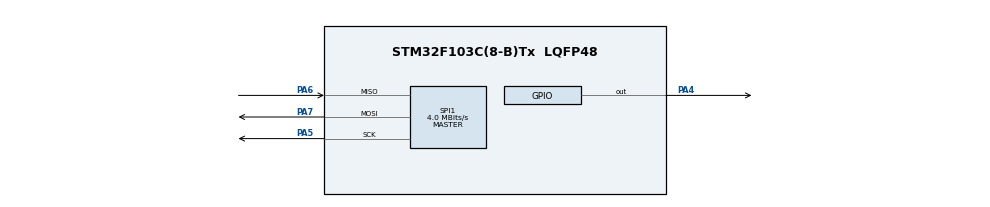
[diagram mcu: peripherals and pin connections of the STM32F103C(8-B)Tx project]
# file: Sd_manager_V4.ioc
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FATFS._MAX_SS=4096
FATFS._USE_LFN=1
Mcu.Family=STM32F1
Mcu.Name=STM32F103C(8-B)Tx
Mcu.Package=LQFP48
NVIC.PriorityGroup=NVIC_PRIORITYGROUP_4
PA13.Mode=Serial_Wire
PA13.Signal=SYS_JTMS-SWDIO
PA14.Mode=Serial_Wire
PA14.Signal=SYS_JTCK-SWCLK
PA4.Signal=GPIO_Output
PA5.Mode=Full_Duplex_Master
PA5.Signal=SPI1_SCK
PA6.Mode=Full_Duplex_Master
PA6.Signal=SPI1_MISO
PA7.Mode=Full_Duplex_Master
PA7.Signal=SPI1_MOSI
ProjectManager.HeapSize=0x200
ProjectManager.StackSize=0x400
ProjectManager.TargetToolchain=STM32CubeIDE
RCC.APB1Freq_Value=8000000
RCC.APB2Freq_Value=8000000
SPI1.CalculateBaudRate=4.0 MBits/s
SPI1.Direction=SPI_DIRECTION_2LINES
SPI1.Mode=SPI_MODE_MASTER
SPI1.VirtualType=VM_MASTER
VP_FATFS_VS_Generic.Mode=User_defined
board=custom

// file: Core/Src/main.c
/* USER CODE BEGIN Header */
/**
  ******************************************************************************
  * @file           : main.c
  * @brief          : Main program body
  ******************************************************************************
  * @attention
  *
  * Copyright (c) 2024 STMicroelectronics.
  * All rights reserved.
  *
  * This software is licensed under terms that can be found in the LICENSE file
  * in the root directory of this software component.
  * If no LICENSE file comes with this software, it is provided AS-IS.
  *
  ******************************************************************************
  */
/* USER CODE END Header */
#include "main.h"
#include "fatfs.h"

#include <stdio.h>

#include "sd_nextion_lib.h"

/* USER CODE BEGIN PTD */
int case_index = 0;
/* USER CODE END PTD */

/* USER CODE BEGIN PD */
FATFS fs;

/* USER CODE END PD */

SPI_HandleTypeDef hspi1;

void SystemClock_Config(void);
static void MX_GPIO_Init(void);
static void MX_SPI1_Init(void);

int main(void)
{

  /* MCU Configuration--------------------------------------------------------*/

  /* Reset of all peripherals, Initializes the Flash interface and the Systick. */
  HAL_Init();

  /* Configure the system clock */
  SystemClock_Config();

  /* Initialize all configured peripherals */
  MX_GPIO_Init();
  MX_SPI1_Init();
  MX_FATFS_Init();
  /* USER CODE BEGIN 2 */

  /* WRITE TEST CSV FILE */
  //HAL_Delay(500);
  //f_mount(&fs, "", 0);
  //f_open(&fil, "filePrueba.csv", FA_OPEN_ALWAYS | FA_WRITE | FA_READ);
  //f_lseek(&fil, fil.fsize);
  //f_puts("Dato1,Dato2,Dato3\n", &fil);
  //f_close(&fil);

  // Montar el sistema de archivos
  if (f_mount(&fs, "", 0) != FR_OK) {
      // Manejar el error de montaje del sistema de archivos
      Error_Handler();
  }

  save_sd(0,"MCU initialized", "timestamp");

  if (verificarSd("data.csv") == 1) {
	  printf("OK: Se pudo acceder a data.csv\n");
  } else {
	  // Manejar el error: archivo no disponible
	  printf("KO: No se pudo acceder a data.csv\n");
  }

  /* USER CODE END 2 */

  /* Infinite loop */
  /* USER CODE BEGIN WHILE */
  while (1)
  {

	 /* Toggle the LED */
	 HAL_GPIO_TogglePin(GPIOC, GPIO_PIN_13);
	 HAL_Delay(200);

	 switch (case_index) {
	 	  case 0:
	 		  //ID_Engine_temp
	 		  save_sd(1, "Engine_temp_Value", "timestamp");
	 		  break;
	 	  case 1:
	 		  //Battery_volt
	 		  save_sd(2, "Valor_Battery_volt_Value", "timestamp");
	 		  break;
	 	  case 2:
	 		  //Speed
	 		  save_sd(3, "Valor_Speed_Value", "timestamp");
	 		  break;
	 	  case 3:
	 		  //Gear
	 		  save_sd(4, "Valor_Gear_Value", "timestamp");
	 		  break;
	 	  case 4:
	 		  //RPMs
	 		  save_sd(5, "Valor_RPM_Value", "timestamp");
	 		  break;
	 	  case 5:
	 		  //Brake_pedal
	 		  save_sd(6, "Valor_Brake_pedal_Value", "timestamp" );
	 		  break;
	 	  case 6:
	 		  //Accel_pedal
	 		  save_sd(7,"Valor_Accel_pedal_Value", "timestamp");
	 		  break;
	 	  default:
	 		  // Manejar el caso por defecto si case_index está fuera de rango
	 		  Error_Handler();
	 		  break;
	   }
	case_index++;
	if (case_index == 7) {
	    case_index = 0;
	}

  }
  /* USER CODE END 3 */
}

void SystemClock_Config(void)
{
  RCC_OscInitTypeDef RCC_OscInitStruct = {0};
  RCC_ClkInitTypeDef RCC_ClkInitStruct = {0};

  /** Initializes the RCC Oscillators according to the specified parameters
  * in the RCC_OscInitTypeDef structure.
  */
  RCC_OscInitStruct.OscillatorType = RCC_OSCILLATORTYPE_HSI;
  RCC_OscInitStruct.HSIState = RCC_HSI_ON;
  RCC_OscInitStruct.HSICalibrationValue = RCC_HSICALIBRATION_DEFAULT;
  RCC_OscInitStruct.PLL.PLLState = RCC_PLL_NONE;
  if (HAL_RCC_OscConfig(&RCC_OscInitStruct) != HAL_OK)
  {
    Error_Handler();
  }

  /** Initializes the CPU, AHB and APB buses clocks
  */
  RCC_ClkInitStruct.ClockType = RCC_CLOCKTYPE_HCLK|RCC_CLOCKTYPE_SYSCLK
                              |RCC_CLOCKTYPE_PCLK1|RCC_CLOCKTYPE_PCLK2;
  RCC_ClkInitStruct.SYSCLKSource = RCC_SYSCLKSOURCE_HSI;
  RCC_ClkInitStruct.AHBCLKDivider = RCC_SYSCLK_DIV1;
  RCC_ClkInitStruct.APB1CLKDivider = RCC_HCLK_DIV1;
  RCC_ClkInitStruct.APB2CLKDivider = RCC_HCLK_DIV1;

  if (HAL_RCC_ClockConfig(&RCC_ClkInitStruct, FLASH_LATENCY_0) != HAL_OK)
  {
    Error_Handler();
  }
}

static void MX_SPI1_Init(void)
{

  /* SPI1 parameter configuration*/
  hspi1.Instance = SPI1;
  hspi1.Init.Mode = SPI_MODE_MASTER;
  hspi1.Init.Direction = SPI_DIRECTION_2LINES;
  hspi1.Init.DataSize = SPI_DATASIZE_8BIT;
  hspi1.Init.CLKPolarity = SPI_POLARITY_LOW;
  hspi1.Init.CLKPhase = SPI_PHASE_1EDGE;
  hspi1.Init.NSS = SPI_NSS_SOFT;
  hspi1.Init.BaudRatePrescaler = SPI_BAUDRATEPRESCALER_2;
  hspi1.Init.FirstBit = SPI_FIRSTBIT_MSB;
  hspi1.Init.TIMode = SPI_TIMODE_DISABLE;
  hspi1.Init.CRCCalculation = SPI_CRCCALCULATION_DISABLE;
  hspi1.Init.CRCPolynomial = 10;
  if (HAL_SPI_Init(&hspi1) != HAL_OK)
  {
    Error_Handler();
  }

}

static void MX_GPIO_Init(void)
{
  GPIO_InitTypeDef GPIO_InitStruct = {0};

  /* GPIO Ports Clock Enable */
  __HAL_RCC_GPIOC_CLK_ENABLE();
  __HAL_RCC_GPIOA_CLK_ENABLE();

  /*Configure GPIO pin Output Level */
  HAL_GPIO_WritePin(GPIOC, GPIO_PIN_13, GPIO_PIN_RESET);

  /*Configure GPIO pin Output Level */
  HAL_GPIO_WritePin(GPIOA, GPIO_PIN_4, GPIO_PIN_RESET);

  /*Configure GPIO pin : PC13 */
  GPIO_InitStruct.Pin = GPIO_PIN_13;
  GPIO_InitStruct.Mode = GPIO_MODE_OUTPUT_PP;
  GPIO_InitStruct.Pull = GPIO_NOPULL;
  GPIO_InitStruct.Speed = GPIO_SPEED_FREQ_LOW;
  HAL_GPIO_Init(GPIOC, &GPIO_InitStruct);

  /*Configure GPIO pin : PA4 */
  GPIO_InitStruct.Pin = GPIO_PIN_4;
  GPIO_InitStruct.Mode = GPIO_MODE_OUTPUT_PP;
  GPIO_InitStruct.Pull = GPIO_NOPULL;
  GPIO_InitStruct.Speed = GPIO_SPEED_FREQ_LOW;
  HAL_GPIO_Init(GPIOA, &GPIO_InitStruct);

}

void Error_Handler(void)
{
  __disable_irq();
  while (1)
  {
  }
}
